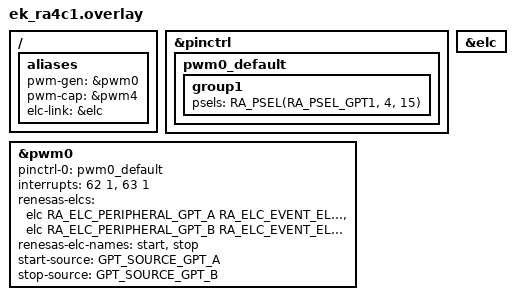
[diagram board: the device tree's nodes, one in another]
/*
 * Copyright (c) 2025 Renesas Electronics Corporation
 *
 * SPDX-License-Identifier: Apache-2.0
 */

#include <zephyr/dt-bindings/pwm/pwm.h>
#include <zephyr/dt-bindings/pwm/ra_pwm.h>

/ {
	aliases {
		pwm-gen = &pwm0;
		pwm-cap = &pwm4;
		elc-link = &elc;
	};
};

&pinctrl {
	pwm0_default: pwm0_default {
		group1 {
			/* GTIOC0A*/
			psels = <RA_PSEL(RA_PSEL_GPT1, 4, 15)>;
		};
	};
};

&pwm0 {
	pinctrl-0 = <&pwm0_default>;
	pinctrl-names = "default";
	interrupts = <62 1>, <63 1>;
	interrupt-names = "gtioca", "overflow";
	status = "okay";
};

&pwm0 {
	renesas-elcs = <&elc RA_ELC_PERIPHERAL_GPT_A RA_ELC_EVENT_ELC_SOFTWARE_EVENT_0>,
		       <&elc RA_ELC_PERIPHERAL_GPT_B RA_ELC_EVENT_ELC_SOFTWARE_EVENT_1>;
	renesas-elc-names = "start", "stop";
	start-source = "GPT_SOURCE_GPT_A";
	stop-source = "GPT_SOURCE_GPT_B";
	status = "okay";
};

&elc {
	status = "okay";
};
